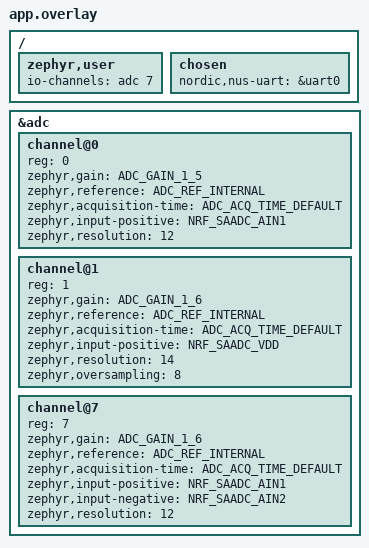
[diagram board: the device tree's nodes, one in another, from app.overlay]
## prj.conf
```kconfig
#
# Copyright (c) 2018 Nordic Semiconductor
#
# SPDX-License-Identifier: LicenseRef-Nordic-5-Clause
#

# Enable the UART driver
CONFIG_UART_ASYNC_API=y
CONFIG_NRFX_UARTE0=y
CONFIG_SERIAL=y

CONFIG_GPIO=y

# Make sure printk is printing to the UART console
CONFIG_CONSOLE=y
CONFIG_UART_CONSOLE=y

CONFIG_HEAP_MEM_POOL_SIZE=2048

CONFIG_BT=y
CONFIG_BT_PERIPHERAL=y
CONFIG_BT_DEVICE_NAME="Nordic_UART_Service"
CONFIG_BT_DEVICE_APPEARANCE=833
CONFIG_BT_MAX_CONN=1
CONFIG_BT_MAX_PAIRED=1

# Enable the NUS service
CONFIG_BT_NUS=y

# Enable bonding
CONFIG_BT_SETTINGS=y
CONFIG_FLASH=y
CONFIG_FLASH_PAGE_LAYOUT=y
CONFIG_FLASH_MAP=y
CONFIG_NVS=y
CONFIG_SETTINGS=y

# Enable DK LED and Buttons library
CONFIG_DK_LIBRARY=y

# This example requires more workqueue stack
CONFIG_SYSTEM_WORKQUEUE_STACK_SIZE=2048

# Config logger
CONFIG_LOG=y
CONFIG_USE_SEGGER_RTT=y
CONFIG_LOG_BACKEND_RTT=y
CONFIG_LOG_BACKEND_UART=n
CONFIG_LOG_PRINTK=n

CONFIG_ASSERT=y

CONFIG_ADC=y
CONFIG_CPP=y

CONFIG_BT_GAP_AUTO_UPDATE_CONN_PARAMS=y

CONFIG_BT=y
CONFIG_BT_DEBUG_LOG=y
CONFIG_BT_SMP=y
CONFIG_BT_L2CAP_TX_BUF_COUNT=5
CONFIG_BT_PERIPHERAL=y

CONFIG_BT_CONN_CTX=y

CONFIG_BT_ATT_PREPARE_COUNT=2
CONFIG_BT_CTLR_RX_BUFFERS=2
CONFIG_BT_DATA_LEN_UPDATE=y
CONFIG_BT_CTLR_PHY_2M=y
CONFIG_BT_HCI_ACL_FLOW_CONTROL=y
CONFIG_BT_GATT_CLIENT=y

CONFIG_BT_BUF_ACL_RX_SIZE=251
CONFIG_BT_L2CAP_TX_MTU=247
CONFIG_BT_BUF_ACL_TX_COUNT=10
CONFIG_BT_BUF_ACL_TX_SIZE=251
CONFIG_BT_CTLR_DATA_LENGTH_MAX=251

CONFIG_BT_CTLR_PHY_CODED=y
CONFIG_BT_CTLR_SDC_MAX_CONN_EVENT_LEN_DEFAULT=4000000
CONFIG_BT_USER_DATA_LEN_UPDATE=y
CONFIG_BT_CTLR_TX_PWR_DYNAMIC_CONTROL=y
```

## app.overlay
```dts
/*
 * Copyright (c) 2022 Nordic Semiconductor ASA
 *
 * SPDX-License-Identifier: LicenseRef-Nordic-5-Clause
 */

/ {
	zephyr,user {
		io-channels = <&adc 7>;
	};
	chosen {
		nordic,nus-uart = &uart0;
	};
};
&adc {
	#address-cells = <1>;
	#size-cells = <0>;

	channel@0 {
		reg = <0>;
		zephyr,gain = "ADC_GAIN_1_5";
		zephyr,reference = "ADC_REF_INTERNAL";
		zephyr,acquisition-time = <ADC_ACQ_TIME_DEFAULT>;
		zephyr,input-positive = <NRF_SAADC_AIN1>; /* P0.03 */
		zephyr,resolution = <12>;
	};

	channel@1 {
		reg = <1>;
		zephyr,gain = "ADC_GAIN_1_6";
		zephyr,reference = "ADC_REF_INTERNAL";
		zephyr,acquisition-time = <ADC_ACQ_TIME_DEFAULT>;
		zephyr,input-positive = <NRF_SAADC_VDD>;
		zephyr,resolution = <14>;
		zephyr,oversampling = <8>;
	};

	channel@7 {
		reg = <7>;
		zephyr,gain = "ADC_GAIN_1_6";
		zephyr,reference = "ADC_REF_INTERNAL";
		zephyr,acquisition-time = <ADC_ACQ_TIME_DEFAULT>;
		zephyr,input-positive = <NRF_SAADC_AIN1>; /* P0.30 */
		zephyr,input-negative = <NRF_SAADC_AIN2>; /* P0.31 */
		zephyr,resolution = <12>;
	};
};
```

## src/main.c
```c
/*
 * Copyright (c) 2020 Libre Solar Technologies GmbH
 *
 * SPDX-License-Identifier: Apache-2.0
 */

#include <inttypes.h>
#include <stddef.h>
#include <stdint.h>
#include <stdlib.h>

#include <zephyr/device.h>
#include <zephyr/devicetree.h>
#include <zephyr/drivers/adc.h>
#include <zephyr/drivers/uart.h>
#include <zephyr/kernel.h>
#include <zephyr/sys/printk.h>
#include <zephyr/sys/util.h>
#include <zephyr/types.h>
#include <zephyr/usb/usb_device.h>
#include <soc.h>

#include "uart_async_adapter.h"

#include <zephyr/bluetooth/bluetooth.h>
#include <zephyr/bluetooth/uuid.h>
#include <zephyr/bluetooth/gatt.h>
#include <zephyr/bluetooth/hci.h>
#include <zephyr/bluetooth/conn.h>

#include <bluetooth/services/lbs.h>
#include <bluetooth/services/nus.h>

#include <dk_buttons_and_leds.h>

#include <zephyr/settings/settings.h>

#include <stdio.h>

#include <zephyr/logging/log.h>

#if !DT_NODE_EXISTS(DT_PATH(zephyr_user)) || \
	!DT_NODE_HAS_PROP(DT_PATH(zephyr_user), io_channels)
#error "No suitable devicetree overlay specified"
#endif

#define DT_SPEC_AND_COMMA(node_id, prop, idx) \
	ADC_DT_SPEC_GET_BY_IDX(node_id, idx),

#define LOG_MODULE_NAME peripheral_uart
LOG_MODULE_REGISTER(LOG_MODULE_NAME);

#define STACKSIZE CONFIG_BT_NUS_THREAD_STACK_SIZE
#define PRIORITY 3

#define DEVICE_NAME CONFIG_BT_DEVICE_NAME
#define DEVICE_NAME_LEN	(sizeof(DEVICE_NAME) - 1)

#define RUN_STATUS_LED DK_LED1
#define RUN_LED_BLINK_INTERVAL 1000

#define CON_STATUS_LED DK_LED2

#define KEY_PASSKEY_ACCEPT DK_BTN1_MSK
#define KEY_PASSKEY_REJECT DK_BTN2_MSK

#define UART_BUF_SIZE CONFIG_BT_NUS_UART_BUFFER_SIZE
#define UART_WAIT_FOR_BUF_DELAY K_MSEC(50)
#define UART_WAIT_FOR_RX CONFIG_BT_NUS_UART_RX_WAIT_TIME
#define NUM_TO_SENT 40

static K_SEM_DEFINE(ble_init_ok, 0, 1);

static struct bt_conn *current_conn;
static struct bt_conn *auth_conn;

static const struct device *uart = DEVICE_DT_GET(DT_CHOSEN(nordic_nus_uart));
static struct k_work_delayable uart_work;

struct uart_data_t {
	void *fifo_reserved;
	uint8_t data[UART_BUF_SIZE];
	uint16_t len;
};

struct fifo_data
{
	void *fifo_reserved;
	char str[50];
	uint16_t len;
};

static K_FIFO_DEFINE(fifo_uart_tx_data);
static K_FIFO_DEFINE(fifo_uart_rx_data);
static K_FIFO_DEFINE(fifo_bt_data);

static const struct bt_data ad[] = {
	BT_DATA_BYTES(BT_DATA_FLAGS, (BT_LE_AD_GENERAL | BT_LE_AD_NO_BREDR)),
	BT_DATA(BT_DATA_NAME_COMPLETE, DEVICE_NAME, DEVICE_NAME_LEN),
};

static const struct bt_data sd[] = {
	BT_DATA_BYTES(BT_DATA_UUID128_ALL, BT_UUID_NUS_VAL),
};

#if CONFIG_BT_NUS_UART_ASYNC_ADAPTER
UART_ASYNC_ADAPTER_INST_DEFINE(async_adapter);
#else
static const struct device *const async_adapter;
#endif

/* Data of ADC io-channels specified in devicetree. */
static const struct adc_dt_spec adc_channels[] = {
	DT_FOREACH_PROP_ELEM(DT_PATH(zephyr_user), io_channels,
			     DT_SPEC_AND_COMMA)
};

uint32_t count = 0;

static K_SEM_DEFINE(saadc_sem, 0, 1);
static void saadc_timer_handler() { k_sem_give(&saadc_sem); }
static K_TIMER_DEFINE(saadc_timer, saadc_timer_handler, NULL);


static void uart_cb(const struct device *dev, struct uart_event *evt, void *user_data)
{
	ARG_UNUSED(dev);

	static size_t aborted_len;
	struct uart_data_t *buf;
	static uint8_t *aborted_buf;
	static bool disable_req;

	switch (evt->type) {
	case UART_TX_DONE:
		LOG_DBG("UART_TX_DONE");
		if ((evt->data.tx.len == 0) ||
		    (!evt->data.tx.buf)) {
			return;
		}

		if (aborted_buf) {
			buf = CONTAINER_OF(aborted_buf, struct uart_data_t,
					   data);
			aborted_buf = NULL;
			aborted_len = 0;
		} else {
			buf = CONTAINER_OF(evt->data.tx.buf, struct uart_data_t,
					   data);
		}

		k_free(buf);

		buf = k_fifo_get(&fifo_uart_tx_data, K_NO_WAIT);
		if (!buf) {
			return;
		}

		if (uart_tx(uart, buf->data, buf->len, SYS_FOREVER_MS)) {
			LOG_WRN("Failed to send data over UART");
		}

		break;

	case UART_RX_RDY:
		LOG_DBG("UART_RX_RDY");
		buf = CONTAINER_OF(evt->data.rx.buf, struct uart_data_t, data);
		buf->len += evt->data.rx.len;

		if (disable_req) {
			return;
		}

		if ((evt->data.rx.buf[buf->len - 1] == '\n') ||
		    (evt->data.rx.buf[buf->len - 1] == '\r')) {
			disable_req = true;
			uart_rx_disable(uart);
		}

		break;

	case UART_RX_DISABLED:
		LOG_DBG("UART_RX_DISABLED");
		disable_req = false;

		buf = k_malloc(sizeof(*buf));
		if (buf) {
			buf->len = 0;
		} else {
			LOG_WRN("Not able to allocate UART receive buffer");
			k_work_reschedule(&uart_work, UART_WAIT_FOR_BUF_DELAY);
			return;
		}

		uart_rx_enable(uart, buf->data, sizeof(buf->data),
			       UART_WAIT_FOR_RX);

		break;

	case UART_RX_BUF_REQUEST:
		LOG_DBG("UART_RX_BUF_REQUEST");
		buf = k_malloc(sizeof(*buf));
		if (buf) {
			buf->len = 0;
			uart_rx_buf_rsp(uart, buf->data, sizeof(buf->data));
		} else {
			LOG_WRN("Not able to allocate UART receive buffer");
		}

		break;

	case UART_RX_BUF_RELEASED:
		LOG_DBG("UART_RX_BUF_RELEASED");
		buf = CONTAINER_OF(evt->data.rx_buf.buf, struct uart_data_t,
				   data);

		if (buf->len > 0) {
			k_fifo_put(&fifo_uart_rx_data, buf);
		} else {
			k_free(buf);
		}

		break;

	case UART_TX_ABORTED:
		LOG_DBG("UART_TX_ABORTED");
		if (!aborted_buf) {
			aborted_buf = (uint8_t *)evt->data.tx.buf;
		}

		aborted_len += evt->data.tx.len;
		buf = CONTAINER_OF(aborted_buf, struct uart_data_t,
				   data);

		uart_tx(uart, &buf->data[aborted_len],
			buf->len - aborted_len, SYS_FOREVER_MS);

		break;

	default:
		break;
	}
}

static void uart_work_handler(struct k_work *item)
{
	struct uart_data_t *buf;

	buf = k_malloc(sizeof(*buf));
	if (buf) {
		buf->len = 0;
	} else {
		LOG_WRN("Not able to allocate UART receive buffer");
		k_work_reschedule(&uart_work, UART_WAIT_FOR_BUF_DELAY);
		return;
	}

	uart_rx_enable(uart, buf->data, sizeof(buf->data), UART_WAIT_FOR_RX);
}

static bool uart_test_async_api(const struct device *dev)
{
	const struct uart_driver_api *api =
			(const struct uart_driver_api *)dev->api;

	return (api->callback_set != NULL);
}

static int uart_init(void)
{
	int err;
	int pos;
	struct uart_data_t *rx;
	struct uart_data_t *tx;

	if (!device_is_ready(uart)) {
		return -ENODEV;
	}

	if (IS_ENABLED(CONFIG_USB_DEVICE_STACK)) {
		err = usb_enable(NULL);
		if (err && (err != -EALREADY)) {
			LOG_ERR("Failed to enable USB");
			return err;
		}
	}

	rx = k_malloc(sizeof(*rx));
	if (rx) {
		rx->len = 0;
	} else {
		return -ENOMEM;
	}

	k_work_init_delayable(&uart_work, uart_work_handler);


	if (IS_ENABLED(CONFIG_BT_NUS_UART_ASYNC_ADAPTER) && !uart_test_async_api(uart)) {
		/* Implement API adapter */
		uart_async_adapter_init(async_adapter, uart);
		uart = async_adapter;
	}

	err = uart_callback_set(uart, uart_cb, NULL);
	if (err) {
		k_free(rx);
		LOG_ERR("Cannot initialize UART callback");
		return err;
	}

	if (IS_ENABLED(CONFIG_UART_LINE_CTRL)) {
		LOG_INF("Wait for DTR");
		/*while (true) {
			uint32_t dtr = 0;

			uart_line_ctrl_get(uart, UART_LINE_CTRL_DTR, &dtr);
			if (dtr) {
				break;
			}
			k_sleep(K_MSEC(100));
		}
		LOG_INF("DTR set");
		err = uart_line_ctrl_set(uart, UART_LINE_CTRL_DCD, 1);
		if (err) {
			LOG_WRN("Failed to set DCD, ret code %d", err);
		}
		err = uart_line_ctrl_set(uart, UART_LINE_CTRL_DSR, 1);
		if (err) {
			LOG_WRN("Failed to set DSR, ret code %d", err);
		}*/
	}

	tx = k_malloc(sizeof(*tx));

	if (tx) {
		pos = snprintf(tx->data, sizeof(tx->data),
			       "Starting Nordic UART service example\r\n");

		if ((pos < 0) || (pos >= sizeof(tx->data))) {
			k_free(rx);
			k_free(tx);
			LOG_ERR("snprintf returned %d", pos);
			return -ENOMEM;
		}

		tx->len = pos;
	} else {
		k_free(rx);
		return -ENOMEM;
	}

	err = uart_tx(uart, tx->data, tx->len, SYS_FOREVER_MS);
	if (err) {
		k_free(rx);
		k_free(tx);
		LOG_ERR("Cannot display welcome message (err: %d)", err);
		return err;
	}

	err = uart_rx_enable(uart, rx->data, sizeof(rx->data), 50);
	if (err) {
		LOG_ERR("Cannot enable uart reception (err: %d)", err);
		/* Free the rx buffer only because the tx buffer will be handled in the callback */
		k_free(rx);
	}

	return err;
}

bool test_ready = false;

static void exchange_func(struct bt_conn *conn, uint8_t att_err,
			  struct bt_gatt_exchange_params *params)
{
	struct bt_conn_info info = {0};
	int err;

	printk("MTU exchange %s\n", att_err == 0 ? "successful" : "failed");
	printk("MTU size is: %d\n", bt_gatt_get_mtu(conn));

	err = bt_conn_get_info(conn, &info);
	if (err) {
		printk("Failed to get connection info %d\n", err);
		return;
	}

	if (info.role == BT_CONN_ROLE_MASTER) {
		test_ready = true;
	}
}

struct bt_gatt_exchange_params exchange_params;

static void connected(struct bt_conn *conn, uint8_t err)
{
	char addr[BT_ADDR_LE_STR_LEN];

	if (err) {
		LOG_ERR("Connection failed (err %u)", err);
		return;
	}

	bt_addr_le_to_str(bt_conn_get_dst(conn), addr, sizeof(addr));
	LOG_INF("Connected %s", addr);

	current_conn = bt_conn_ref(conn);

	exchange_params.func = exchange_func;

	printk("MTU size is: %d\n", bt_gatt_get_mtu(current_conn));

	err = bt_gatt_exchange_mtu(current_conn, &exchange_params);
	if (err) {
		printk("MTU exchange failed (err %d)\n", err);
	} else {
		printk("MTU exchange pending\n");
	}

	dk_set_led_on(CON_STATUS_LED);

	struct bt_conn_le_data_len_param data_len_param;

	data_len_param.tx_max_len = 200; // byte
	data_len_param.tx_max_time = 3750; // us

	err = bt_conn_le_data_len_update(current_conn, &data_len_param);
	if (err)
	{
		printk("LE data length update failed: %d\n", err);
	}
        else
	{
		printk("LE data length update success \n");
	}

}

static void disconnected(struct bt_conn *conn, uint8_t reason)
{
	char addr[BT_ADDR_LE_STR_LEN];

	bt_addr_le_to_str(bt_conn_get_dst(conn), addr, sizeof(addr));

	LOG_INF("Disconnected: %s (reason %u)", addr, reason);

	if (auth_conn) {
		bt_conn_unref(auth_conn);
		auth_conn = NULL;
	}

	if (current_conn) {
		bt_conn_unref(current_conn);
		current_conn = NULL;
		dk_set_led_off(CON_STATUS_LED);
	}
}

#ifdef CONFIG_BT_NUS_SECURITY_ENABLED
static void security_changed(struct bt_conn *conn, bt_security_t level,
			     enum bt_security_err err)
{
	char addr[BT_ADDR_LE_STR_LEN];

	bt_addr_le_to_str(bt_conn_get_dst(conn), addr, sizeof(addr));

	if (!err) {
		LOG_INF("Security changed: %s level %u", addr, level);
	} else {
		LOG_WRN("Security failed: %s level %u err %d", addr,
			level, err);
	}
}
#endif

BT_CONN_CB_DEFINE(conn_callbacks) = {
	.connected    = connected,
	.disconnected = disconnected,
#ifdef CONFIG_BT_NUS_SECURITY_ENABLED
	.security_changed = security_changed,
#endif
};

#if defined(CONFIG_BT_NUS_SECURITY_ENABLED)
static void auth_passkey_display(struct bt_conn *conn, unsigned int passkey)
{
	char addr[BT_ADDR_LE_STR_LEN];

	bt_addr_le_to_str(bt_conn_get_dst(conn), addr, sizeof(addr));

	LOG_INF("Passkey for %s: %06u", addr, passkey);
}

static void auth_passkey_confirm(struct bt_conn *conn, unsigned int passkey)
{
	char addr[BT_ADDR_LE_STR_LEN];

	auth_conn = bt_conn_ref(conn);

	bt_addr_le_to_str(bt_conn_get_dst(conn), addr, sizeof(addr));

	LOG_INF("Passkey for %s: %06u", addr, passkey);
	LOG_INF("Press Button 1 to confirm, Button 2 to reject.");
}


static void auth_cancel(struct bt_conn *conn)
{
	char addr[BT_ADDR_LE_STR_LEN];

	bt_addr_le_to_str(bt_conn_get_dst(conn), addr, sizeof(addr));

	LOG_INF("Pairing cancelled: %s", addr);
}


static void pairing_complete(struct bt_conn *conn, bool bonded)
{
	char addr[BT_ADDR_LE_STR_LEN];

	bt_addr_le_to_str(bt_conn_get_dst(conn), addr, sizeof(addr));

	LOG_INF("Pairing completed: %s, bonded: %d", addr, bonded);
}


static void pairing_failed(struct bt_conn *conn, enum bt_security_err reason)
{
	char addr[BT_ADDR_LE_STR_LEN];

	bt_addr_le_to_str(bt_conn_get_dst(conn), addr, sizeof(addr));

	LOG_INF("Pairing failed conn: %s, reason %d", addr, reason);
}


static struct bt_conn_auth_cb conn_auth_callbacks = {
	.passkey_display = auth_passkey_display,
	.passkey_confirm = auth_passkey_confirm,
	.cancel = auth_cancel,
};

static struct bt_conn_auth_info_cb conn_auth_info_callbacks = {
	.pairing_complete = pairing_complete,
	.pairing_failed = pairing_failed
};
#else
static struct bt_conn_auth_cb conn_auth_callbacks;
static struct bt_conn_auth_info_cb conn_auth_info_callbacks;
#endif

static void bt_receive_cb(struct bt_conn *conn, const uint8_t *const data,
			  uint16_t len)
{
	int err;
	char addr[BT_ADDR_LE_STR_LEN] = {0};

	bt_addr_le_to_str(bt_conn_get_dst(conn), addr, ARRAY_SIZE(addr));

	LOG_INF("Received data from: %s", addr);

	for (uint16_t pos = 0; pos != len;) {
		struct uart_data_t *tx = k_malloc(sizeof(*tx));

		if (!tx) {
			LOG_WRN("Not able to allocate UART send data buffer");
			return;
		}

		/* Keep the last byte of TX buffer for potential LF char. */
		size_t tx_data_size = sizeof(tx->data) - 1;

		if ((len - pos) > tx_data_size) {
			tx->len = tx_data_size;
		} else {
			tx->len = (len - pos);
		}

		memcpy(tx->data, &data[pos], tx->len);

		pos += tx->len;

		/* Append the LF character when the CR character triggered
		 * transmission from the peer.
		 */
		if ((pos == len) && (data[len - 1] == '\r')) {
			tx->data[tx->len] = '\n';
			tx->len++;
		}

		err = uart_tx(uart, tx->data, tx->len, SYS_FOREVER_MS);
		if (err) {
			k_fifo_put(&fifo_uart_tx_data, tx);
		}
	}
}

static struct bt_nus_cb nus_cb = {
	.received = bt_receive_cb,
};

void error(void)
{
	dk_set_leds_state(DK_ALL_LEDS_MSK, DK_NO_LEDS_MSK);

	while (true) {
		/* Spin for ever */
		k_sleep(K_MSEC(1000));
	}
}

#ifdef CONFIG_BT_NUS_SECURITY_ENABLED
static void num_comp_reply(bool accept)
{
	if (accept) {
		bt_conn_auth_passkey_confirm(auth_conn);
		LOG_INF("Numeric Match, conn %p", (void *)auth_conn);
	} else {
		bt_conn_auth_cancel(auth_conn);
		LOG_INF("Numeric Reject, conn %p", (void *)auth_conn);
	}

	bt_conn_unref(auth_conn);
	auth_conn = NULL;
}

void button_changed(uint32_t button_state, uint32_t has_changed)
{
	uint32_t buttons = button_state & has_changed;

	if (auth_conn) {
		if (buttons & KEY_PASSKEY_ACCEPT) {
			num_comp_reply(true);
		}

		if (buttons & KEY_PASSKEY_REJECT) {
			num_comp_reply(false);
		}
	}
}
#endif /* CONFIG_BT_NUS_SECURITY_ENABLED */

static void configure_gpio(void)
{
	int err;

#ifdef CONFIG_BT_NUS_SECURITY_ENABLED
	err = dk_buttons_init(button_changed);
	if (err) {
		LOG_ERR("Cannot init buttons (err: %d)", err);
	}
#endif /* CONFIG_BT_NUS_SECURITY_ENABLED */

	err = dk_leds_init();
	if (err) {
		LOG_ERR("Cannot init LEDs (err: %d)", err);
	}
}

struct adc_sequence sequence;
uint16_t buf;
bool flagSend = false; 

const int MTU_SIZE = 244;

void ble_write_thread(void)
{
	int count = 0;
	char Bufstr[300];
	while (1)
	{
		//printk("Entered\n");
		struct fifo_data *buf = k_fifo_get(&fifo_bt_data,
						     K_FOREVER);
		if (buf -> len != 0)
		{
			count++;
			Bufstr[(count-1) * 6] = buf->str[0];
			Bufstr[((count-1) * 6) + 1] = buf->str[1];
			Bufstr[((count-1) * 6) + 2] = buf->str[2];
			Bufstr[((count-1) * 6) + 3] = buf->str[3];
			Bufstr[((count-1) * 6) + 4] = buf->str[4];
			Bufstr[((count-1) * 6) + 5] = buf->str[5];

			if (count == NUM_TO_SENT)
			{
				bt_nus_send(NULL, Bufstr, count * 6);
				//printk("%d\n",strlen(Bufstr));

				count = 0;

				memset(Bufstr, 0, sizeof Bufstr);
			}
		}
		//printk("%u\n", bt_nus_get_mtu(current_conn));
		/*
		for (int i = 0;i < buf->len;i++)
		{
			printk("%d ",(buf -> str)[i]);
		}
		printk("\n");
		*/

		//k_free(buf);
	}
}

K_THREAD_DEFINE(ble_write_thread_id, STACKSIZE, ble_write_thread, NULL, NULL,
		NULL, PRIORITY, 0, 0);

K_THREAD_STACK_DEFINE(my_stack_area, STACKSIZE);
struct k_thread my_thread_data;

struct fifo_data tx_data;

int main(void)
{
	int err = 0;
	uint32_t count = 0;
	int groupcnt = 0;
	char BufferStr[10];
	int blink_status = 0;

	configure_gpio();

	err = uart_init();
	if (err) {
		error();
	}

	if (IS_ENABLED(CONFIG_BT_NUS_SECURITY_ENABLED)) {
		err = bt_conn_auth_cb_register(&conn_auth_callbacks);
		if (err) {
			printk("Failed to register authorization callbacks.\n");
			return 0;
		}

		err = bt_conn_auth_info_cb_register(&conn_auth_info_callbacks);
		if (err) {
			printk("Failed to register authorization info callbacks.\n");
			return 0;
		}
	}

	err = bt_enable(NULL);
	if (err) {
		error();
	}

	LOG_INF("Bluetooth initialized");

	k_sem_give(&ble_init_ok);

	if (IS_ENABLED(CONFIG_SETTINGS)) {
		settings_load();
	}

	err = bt_nus_init(&nus_cb);
	if (err) {
		LOG_ERR("Failed to initialize UART service (err: %d)", err);
		return 0;
	}

	err = bt_le_adv_start(BT_LE_ADV_CONN, ad, ARRAY_SIZE(ad), sd,
			      ARRAY_SIZE(sd));
	if (err) {
		LOG_ERR("Advertising failed to start (err %d)", err);
		return 0;
	}

	sequence.buffer = &buf;
		/* buffer size in bytes, not number of samples */
	sequence.buffer_size = sizeof(buf);

	//printk("HERE\n");

	/* Don't go any further until BLE is initialized */
	for (size_t i = 0U; i < ARRAY_SIZE(adc_channels); i++) {
		if (!device_is_ready(adc_channels[i].dev)) {
			printk("ADC controller device %s not ready\n", adc_channels[i].dev->name);
			return 0;
		}

		err = adc_channel_setup_dt(&adc_channels[i]);
		if (err < 0) {
			printk("Could not setup channel #%d (%d)\n", i, err);
			return 0;
		}
	}

	//k_tid_t my_tid = k_thread_create(&my_thread_data, my_stack_area, K_THREAD_STACK_SIZEOF(STACKSIZE), ble_write_thread, NULL, NULL,
	//	NULL, PRIORITY, 0, K_NO_WAIT);
	
	//printk("FINISHED\n");

	/*while (1)
	{
		printk("I am awake\n");
		k_sleep(K_MSEC(1000));
	}*/

	/* Configure channels individually prior to sampling. */

	for (size_t i = 0U; i < ARRAY_SIZE(adc_channels); i++) {
		if (!device_is_ready(adc_channels[i].dev)) {
			printk("ADC controller device %s not ready\n", adc_channels[i].dev->name);
			return 0;
		}

		err = adc_channel_setup_dt(&adc_channels[i]);
		if (err < 0) {
			printk("Could not setup channel #%d (%d)\n", i, err);
			return 0;
		}
	}

	int timer_interval_us = 2300;
    k_timer_start(&saadc_timer, K_NO_WAIT, K_USEC(timer_interval_us)); // 20ms一次 每秒钟50次？ 这么低吗

	groupcnt = 20;

	int64_t time_stamp;
	int64_t milliseconds_spent;
	int16_t cntnum = 0;

	/* capture initial time stamp */
	
	time_stamp = k_uptime_get();

	while (1) {
		//printk("ADC reading[%u]:\n", count++);
		k_sem_take(&saadc_sem, K_FOREVER);
		count++;
		cntnum++;

		for (size_t i = 0U; i < ARRAY_SIZE(adc_channels); i++) {
			int32_t val_mv;

			(void)adc_sequence_init_dt(&adc_channels[i], &sequence);

			err = adc_read(adc_channels[i].dev, &sequence);
			if (err < 0) {
				printk("Could not read (%d)\n", err);
				continue;
			}

			if (adc_channels[i].channel_cfg.differential) {
				val_mv = (int32_t)((int16_t)buf);
			} else {
				val_mv = (int32_t)buf;
			}  
			//printk("%"PRId32, val_mv);
			err = adc_raw_to_millivolts_dt(&adc_channels[i],
						       &val_mv);

			if (err < 0) {
				printk(" (value in mV not available)\n");
			} else {
				//printk(" = %"PRId32" mV\n", val_mv);
			}

			val_mv += 3000;

			int64_t tmptime = k_uptime_get() - time_stamp;

			BufferStr[0] = val_mv & 0xFF;
			BufferStr[1] = val_mv >> 8;
			BufferStr[2] = tmptime & 0xFF;
			BufferStr[3] = (tmptime >> 8) & 0xFF;
			BufferStr[4] = (tmptime >> 16) & 0xFF;
			BufferStr[5] = (tmptime >> 24) & 0xFF;

			tx_data.len = strlen(BufferStr);
			strcpy(tx_data.str, BufferStr);

			k_fifo_put(&fifo_bt_data, &tx_data);
			memset(BufferStr ,0 , sizeof BufferStr);

			//printk("%lld %d\n", tmptime, val_mv);

			if (count == 10000)
			{
				printk("START\n");
			}
			else if (count == 20000)
			{
				printk("%lli\n", (k_uptime_get() - time_stamp));
			}
		}

		//dk_set_led(RUN_STATUS_LED, (++blink_status) % 2);
		//k_msleep(2);

	}

	return 0;
}
```
